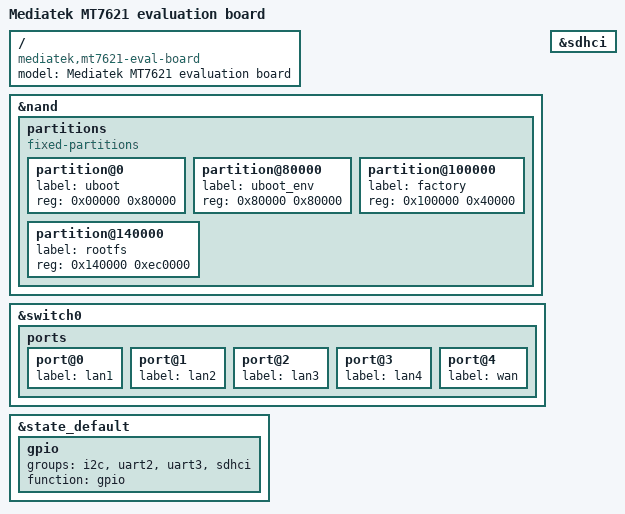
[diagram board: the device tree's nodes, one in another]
#include "mt7621.dtsi"

/ {
	compatible = "mediatek,mt7621-eval-board", "mediatek,mt7621-soc";
	model = "Mediatek MT7621 evaluation board";
};

&nand {
	status = "okay";

	partitions {
		compatible = "fixed-partitions";
		#address-cells = <1>;
		#size-cells = <1>;

		partition@0 {
			label = "uboot";
			reg = <0x00000 0x80000>; /* 64 KB */
		};

		partition@80000 {
			label = "uboot_env";
			reg = <0x80000 0x80000>; /* 64 KB */
		};

		partition@100000 {
			label = "factory";
			reg = <0x100000 0x40000>;
		};

		partition@140000 {
			label = "rootfs";
			reg = <0x140000 0xec0000>;
		};
	};
};

&sdhci {
	status = "okay";
};

&switch0 {
	ports {
		port@0 {
			status = "okay";
			label = "lan1";
		};

		port@1 {
			status = "okay";
			label = "lan2";
		};

		port@2 {
			status = "okay";
			label = "lan3";
		};

		port@3 {
			status = "okay";
			label = "lan4";
		};

		port@4 {
			status = "okay";
			label = "wan";
		};
	};
};

&state_default {
	gpio {
		groups = "i2c", "uart2", "uart3", "sdhci";
		function = "gpio";
	};
};
